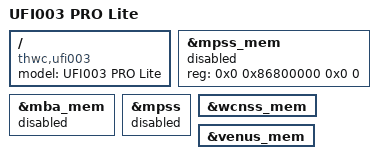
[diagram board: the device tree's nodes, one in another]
// SPDX-License-Identifier: GPL-2.0-only

/dts-v1/;

#include "msm8916-thwc-ufi003-pro.dts"

/ {
	model = "UFI003 PRO Lite";
	compatible = "thwc,ufi003", "qcom,msm8916";
};

&mpss_mem {
	reg = <0x0 0x86800000 0x0 0>;
	status = "disabled";
};

&mba_mem {
	status = "disabled";
};

&mpss {
	status = "disabled";
};

&wcnss_mem {
	status = "okay";
};

&venus_mem {
	status = "okay";
};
